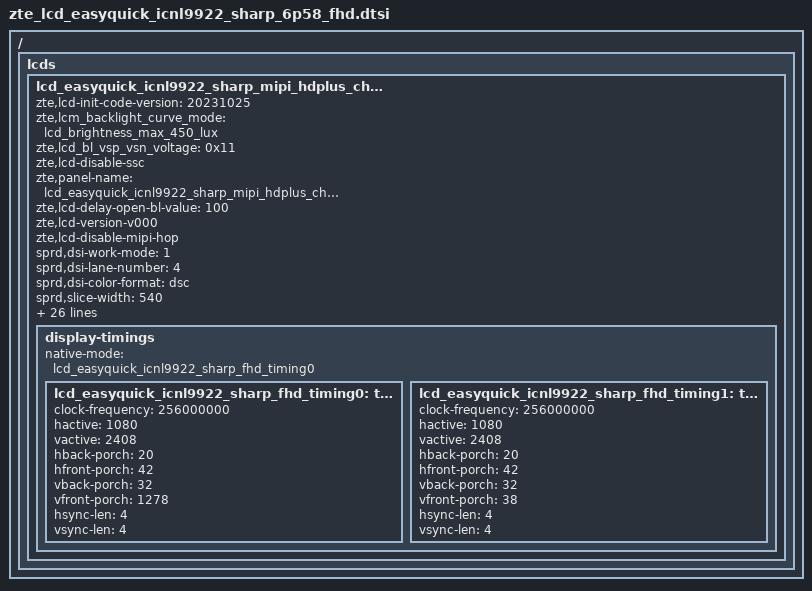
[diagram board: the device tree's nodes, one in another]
/ {
	fragment {
		target-path = "/";
		__overlay__ {
			lcds {
				lcd_easyquick_icnl9922_sharp_mipi_hdplus_chipone: lcd_easyquick_icnl9922_sharp_mipi_hdplus_chipone {
					zte,lcd-init-code-version = "20231025";

					zte,lcm_backlight_curve_mode = "lcd_brightness_max_450_lux";
					zte,lcd_bl_vsp_vsn_voltage = <0x11>;
					zte,lcd-disable-ssc;
					zte,panel-name = "lcd_easyquick_icnl9922_sharp_mipi_hdplus_chipone";
					zte,lcd-delay-open-bl-value = <100>;
					zte,lcd-version-v000;
					zte,lcd-disable-mipi-hop;

					sprd,dsi-work-mode = <1>;
					sprd,dsi-lane-number = <4>;
					sprd,dsi-color-format = "dsc";
					sprd,slice-width = <540>;
					sprd,slice-height = <8>;
					sprd,output-bpc = <8>;
					sprd,dsc-enable = <1>;
					sprd,dual-dsi-enable = <0>;
					zte,dsc-mode = <5>;

					sprd,phy-bit-clock = <819200>;
					sprd,phy-escape-clock = <20000>;/* kHz */

					sprd,width-mm = <68430>;
					sprd,height-mm = <152570>;

					sprd,esd-check-enable = <1>;/* 0:close , 1:open */
					sprd,esd-check-mode = <1>;/* 0:REG ,1:TE  */
					sprd,esd-check-period = <2000>;
					sprd,esd-check-register = <0x0A>;
					sprd,esd-check-value = <0x9C>;

					sprd,dphy-taget-val = <5>;

					sprd,reset-on-sequence = <1 5>, <0 10>, <1 35>;
					sprd,reset-off-sequence = <1 20>;

					sprd,use-gen-write;
					sprd,initial-command = [
						39 00 00 04 F0 99 22 0C
						39 00 00 21 B2 02 01 05 04 11 22 05 04 11 00 00 00 00 00 00 00 00 00 00 00 00 00 00 00 00 55 55 05 10 20 11 00
						39 00 00 21 B4 31 01 01 01 81 00 00 00 00 00 00 00 00 00 C0 03 F0 30 00 00 00 00 00 00 00 00 C0 00 0F C0 03 FF
						39 00 00 21 B6 80 82 82 82 82 82 82 E4 E3 E2 1E 1D 1C 00 0C 12 10 0E 28 00 00 00 00 00 80 38 1F 00 00 00 00 00
						39 00 00 21 B7 80 82 82 82 82 82 82 E4 E3 E2 1E 1D 1C 00 0D 13 11 0F 29 00 00 00 00 00 80 38 1F 00 00 00 00 00
						39 00 00 21 B8 02 01 01 81 00 00 00 00 00 00 1F 00 00 00 00 00 00 00 00 00 00 00 00 00 00 00 00 0C 00 00 00 00
						39 00 00 21 B9 12 33 21 12 33 21 12 33 21 12 33 21 12 33 21 12 33 21 12 33 21 12 33 21 00 00 0F 00 00 00 00 02
						39 00 00 21 BA 00 55 55 55 55 55 55 55 55 55 55 55 55 AA AA AA AA AA AA AA AA AA AA AA AA 00 00 00 00 00 00 00
						39 00 00 21 BB 01 02 03 0A 04 13 14 52 16 5C 00 15 16 00 00 00 00 00 00 00 00 00 00 00 00 00 00 00 00 00 00 00
						39 00 00 21 BC 00 00 00 00 04 00 FF F8 0B 11 50 5C 55 99 00 00 00 00 00 00 00 00 00 00 00 00 00 00 00 00 00 00
						39 00 00 07 BD A1 A2 52 2E 00 8F
						39 00 00 21 BE 23 14 0F AA 43 35 33 2E 14 00 00 3A 00 00 00 B2 AF B2 AF 00 00 33 00 00 00 00 00 00 00 00 00 00
						39 00 00 21 C4 0C 93 A8 28 00 3C 02 00 00 0A 26 48 91 B3 75 00 F0 00 00 00 00 00 00 00 00 00 00 00 00 00 00 00
						39 00 00 16 C0 40 93 FF FF FF 3F FF 00 FF 00 CC 04 12 35 67 89 A0 FF FF F0 0B
						39 00 00 1C C7 77 77 77 77 77 76 54 32 10 77 77 77 77 77 76 54 32 10 33 00 01 FF FF 00 F5 F5 00
						39 00 00 21 80 FF F4 E5 DA D2 CB C5 BF BB AB A0 97 8F 88 82 77 6E 66 5F 5F 59 53 4C 45 41 3C 37 31 2A 20 1E 1B
						39 00 00 21 81 FF F4 E5 DA D2 CB C5 BF BB AB A0 97 8F 88 82 77 6E 66 5F 5F 59 53 4C 45 41 3C 37 31 2A 20 1E 1B
						39 00 00 21 82 FF F4 E5 DA D2 CB C5 BF BB AB A0 97 8F 88 82 77 6E 66 5F 5F 59 53 4C 45 41 3C 37 31 2A 20 1E 1B
						39 00 00 21 83 09 17 13 0F 09 01 00 17 13 0F 09 01 00 17 13 0F 09 01 00 09 07 05 03 01 00 09 07 05 03 01 00 09
						39 00 00 21 84 07 05 03 01 00 EB 93 34 57 F4 09 26 30 B0 CE B9 33 45 7F 40 92 63 0B 0C EB 93 34 57 F4 09 26 30
						39 00 00 1F 85 B0 CC 00 00 00 00 00 00 00 00 00 C0 00 00 00 00 00 00 00 00 0C 00 00 00 00 00 00 00 00 00
						39 00 00 21 C1 00 00 20 26 C0 04 14 2A 04 68 19 22 50 01 11 07 5F FF A0 00 93 2A 20 00 00 00 00 00 00 00 00 00
						39 00 00 10 70 41 12 00 05 00 5A 00 6F 00 77 00 31 02 00 20
						39 00 00 21 71 11 00 00 89 30 80 09 68 04 38 00 08 02 1C 02 1C 02 00 02 0E 00 20 00 BB 00 07 00 0C 0D B7 0C B7
						39 00 00 21 72 18 00 10 F0 03 0C 20 00 06 0B 0B 33 0E 1C 2A 38 46 54 62 69 70 77 79 7B 7D 7E 01 02 01 00 09 40
						39 00 00 19 73 09 BE 19 FC 19 FA 19 F8 1A 38 1A 78 1A B6 2A F6 2B 34 2B 74 3B 74 6B F4
						39 00 00 21 B3 70 03 01 07 81 00 00 00 7A 00 00 00 00 00 C0 03 F0 30 00 00 00 00 00 00 00 00 C0 00 0F C0 03 FF
						39 00 00 21 C3 00 00 00 00 00 02 28 28 2B 14 14 14 00 FF 40 50 2A 2A 2A 2A 2A 2A 2A 2A 00 18 00 00 00 00 00 00
						39 00 00 21 9D 00 00 00 22 2C 4E 58 7A 50 60 68 78 80 90 00 00 00 00 00 00 00 00 00 00 00 00 00 00 00 00 00 00
						39 00 00 21 C5 02 60 D0 9E 82 04 02 02 08 04 10 43 05 08 00 20 0D 0A 06 12 80 FF 01 14 38 00 00 00 00 00 00 00
						39 00 00 21 C6 8C 08 26 4A 4A 20 3F 02 0D 0D 06 00 1C 00 00 00 00 00 00 00 00 00 00 00 00 00 00 00 00 00 00 00
						39 00 00 21 99 91 F6 00 3F 00 7A 00 30 22 03 A2 00 B5 00 2A 08 2A 08 00 00 00 00 00 00 00 00 00 00 00 00 00 00
						39 00 00 21 9A 11 A5 00 00 FF 00 0A 00 57 00 22 6A 00 D8 D8 00 00 00 00 00 00 00 00 00 00 00 00 00 00 00 00 00
						39 00 00 03 C2 00 03
						39 00 00 04 F0 00 00 00
						39 00 00 03 35 00 00
						39 78 00 03 11 00 00
						39 14 00 03 29 00 00
						39 01 00 03 AC 05 00
					];
					zte,initial-command-fps90 = [
						39 00 00 04 F0 99 22 0C
						39 00 00 21 B2 02 01 05 04 11 22 05 04 11 00 00 00 00 00 00 00 00 00 00 00 00 00 00 00 00 55 55 05 10 20 11 00
						39 00 00 21 B4 31 01 01 01 81 00 00 00 00 00 00 00 00 00 C0 03 F0 30 00 00 00 00 00 00 00 00 C0 00 0F C0 03 FF
						39 00 00 21 B6 80 82 82 82 82 82 82 E4 E3 E2 1E 1D 1C 00 0C 12 10 0E 28 00 00 00 00 00 80 38 1F 00 00 00 00 00
						39 00 00 21 B7 80 82 82 82 82 82 82 E4 E3 E2 1E 1D 1C 00 0D 13 11 0F 29 00 00 00 00 00 80 38 1F 00 00 00 00 00
						39 00 00 21 B8 02 01 01 81 00 00 00 00 00 00 1F 00 00 00 00 00 00 00 00 00 00 00 00 00 00 00 00 0C 00 00 00 00
						39 00 00 21 B9 12 33 21 12 33 21 12 33 21 12 33 21 12 33 21 12 33 21 12 33 21 12 33 21 00 00 0F 00 00 00 00 02
						39 00 00 21 BA 00 55 55 55 55 55 55 55 55 55 55 55 55 AA AA AA AA AA AA AA AA AA AA AA AA 00 00 00 00 00 00 00
						39 00 00 21 BB 01 02 03 0A 04 13 14 52 16 5C 00 15 16 00 00 00 00 00 00 00 00 00 00 00 00 00 00 00 00 00 00 00
						39 00 00 21 BC 00 00 00 00 04 00 FF F8 0B 11 50 5C 55 99 00 00 00 00 00 00 00 00 00 00 00 00 00 00 00 00 00 00
						39 00 00 07 BD A1 A2 52 2E 00 8F
						39 00 00 21 BE 23 14 0F AA 43 35 33 2E 14 00 00 3A 00 00 00 B2 AF B2 AF 00 00 33 00 00 00 00 00 00 00 00 00 00
						39 00 00 21 C4 0C 93 A8 28 00 3C 02 00 00 0A 26 48 91 B3 75 00 F0 00 00 00 00 00 00 00 00 00 00 00 00 00 00 00
						39 00 00 16 C0 40 93 FF FF FF 3F FF 00 FF 00 CC 04 12 35 67 89 A0 FF FF F0 0B
						39 00 00 1C C7 77 77 77 77 77 76 54 32 10 77 77 77 77 77 76 54 32 10 33 00 01 FF FF 00 F5 F5 00
						39 00 00 21 80 FF F4 E5 DA D2 CB C5 BF BB AB A0 97 8F 88 82 77 6E 66 5F 5F 59 53 4C 45 41 3C 37 31 2A 20 1E 1B
						39 00 00 21 81 FF F4 E5 DA D2 CB C5 BF BB AB A0 97 8F 88 82 77 6E 66 5F 5F 59 53 4C 45 41 3C 37 31 2A 20 1E 1B
						39 00 00 21 82 FF F4 E5 DA D2 CB C5 BF BB AB A0 97 8F 88 82 77 6E 66 5F 5F 59 53 4C 45 41 3C 37 31 2A 20 1E 1B
						39 00 00 21 83 09 17 13 0F 09 01 00 17 13 0F 09 01 00 17 13 0F 09 01 00 09 07 05 03 01 00 09 07 05 03 01 00 09
						39 00 00 21 84 07 05 03 01 00 EB 93 34 57 F4 09 26 30 B0 CE B9 33 45 7F 40 92 63 0B 0C EB 93 34 57 F4 09 26 30
						39 00 00 1F 85 B0 CC 00 00 00 00 00 00 00 00 00 C0 00 00 00 00 00 00 00 00 0C 00 00 00 00 00 00 00 00 00
						39 00 00 21 C1 00 00 20 26 C0 04 14 2A 04 68 19 22 50 01 11 07 5F FF A0 00 93 2A 20 00 00 00 00 00 00 00 00 00
						39 00 00 10 70 41 12 00 05 00 5A 00 6F 00 77 00 31 02 00 20
						39 00 00 21 71 11 00 00 89 30 80 09 68 04 38 00 08 02 1C 02 1C 02 00 02 0E 00 20 00 BB 00 07 00 0C 0D B7 0C B7
						39 00 00 21 72 18 00 10 F0 03 0C 20 00 06 0B 0B 33 0E 1C 2A 38 46 54 62 69 70 77 79 7B 7D 7E 01 02 01 00 09 40
						39 00 00 19 73 09 BE 19 FC 19 FA 19 F8 1A 38 1A 78 1A B6 2A F6 2B 34 2B 74 3B 74 6B F4
						39 00 00 21 B3 70 03 01 07 81 00 00 00 7A 00 00 00 00 00 C0 03 F0 30 00 00 00 00 00 00 00 00 C0 00 0F C0 03 FF
						39 00 00 21 C3 00 00 00 00 00 02 28 28 2B 14 14 14 00 FF 40 50 2A 2A 2A 2A 2A 2A 2A 2A 00 18 00 00 00 00 00 00
						39 00 00 21 9D 00 00 00 22 2C 4E 58 7A 50 60 68 78 80 90 00 00 00 00 00 00 00 00 00 00 00 00 00 00 00 00 00 00
						39 00 00 21 C5 02 60 D0 9E 82 04 02 02 08 04 10 43 05 08 00 20 0D 0A 06 12 80 FF 01 14 38 00 00 00 00 00 00 00
						39 00 00 21 C6 8C 08 26 4A 4A 20 3F 02 0D 0D 06 00 1C 00 00 00 00 00 00 00 00 00 00 00 00 00 00 00 00 00 00 00
						39 00 00 21 99 91 F6 00 3F 00 7A 00 30 22 03 A2 00 B5 00 2A 08 2A 08 00 00 00 00 00 00 00 00 00 00 00 00 00 00
						39 00 00 21 9A 11 A5 00 00 FF 00 0A 00 57 00 22 6A 00 D8 D8 00 00 00 00 00 00 00 00 00 00 00 00 00 00 00 00 00
						39 00 00 03 C2 00 03
						39 00 00 04 F0 00 00 00
						39 00 00 03 35 00 00
						39 78 00 03 11 00 00
						39 14 00 03 29 00 00
						39 01 00 03 AC 05 00
					];

					sprd,sleep-in-command = [
						39 00 00 04 F0 99 22 0C
						39 00 00 09 BB 01 02 03 0A 04 13 14 12
						39 00 00 04 F0 00 00 00
						39 00 00 03 AC 0A 00
						39 14 00 03 28 00 00
						39 78 00 03 10 00 00
						];
					sprd,sleep-out-command = [
						05 78 00 01 11
						05 14 00 01 29
						];
					display-timings {
						native-mode = <&lcd_easyquick_icnl9922_sharp_fhd_timing0>;
						lcd_easyquick_icnl9922_sharp_fhd_timing0: timing0 {
							clock-frequency = <256000000>;
							hactive = <1080>;
							vactive = <2408>;
							hback-porch = <20>;
							hfront-porch = <42>;
							vback-porch = <32>;
							vfront-porch = <1278>;
							hsync-len = <4>;
							vsync-len = <4>;
						};
						lcd_easyquick_icnl9922_sharp_fhd_timing1: timing1 {
							clock-frequency = <256000000>;
							hactive = <1080>;
							vactive = <2408>;
							hback-porch = <20>;
							hfront-porch = <42>;
							vback-porch = <32>;
							vfront-porch = <38>;
							hsync-len = <4>;
							vsync-len = <4>;
						};
					};
				};
			};
		};
	};
};
